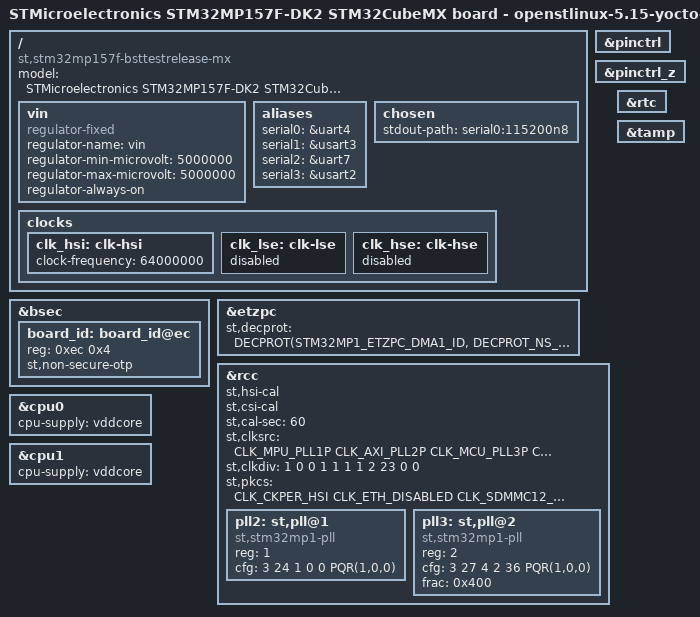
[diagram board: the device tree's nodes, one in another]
/* SPDX-License-Identifier: (GPL-2.0+ OR BSD-3-Clause) */
/*
 * Copyright (C) STMicroelectronics 2024 - All Rights Reserved
 * Author: STM32CubeMX code generation for STMicroelectronics.
 */

/* For more information on Device Tree configuration, please refer to
 * https://wiki.st.com/stm32mpu/wiki/Category:Device_tree_configuration
 */

/dts-v1/;
#include <dt-bindings/pinctrl/stm32-pinfunc.h>
#include <dt-bindings/clock/stm32mp1-clksrc.h>
#include <dt-bindings/soc/st,stm32-etzpc.h>

#include "stm32mp157.dtsi"
#include "stm32mp15xf.dtsi"
#include "stm32mp15xxac-pinctrl.dtsi"
/* !!! log : Warning - DDR not configured: unknown DDR dtsi  !!! */
/*#include "???-ddr.dtsi"*/

/* USER CODE BEGIN includes */
#include <dt-bindings/power/stm32mp1-power.h>
/* USER CODE END includes */

/ {
	model = "STMicroelectronics STM32MP157F-DK2 STM32CubeMX board - openstlinux-5.15-yocto-kirkstone-mp1-v22.11.23";
	compatible = "st,stm32mp157f-bsttestrelease-mx", "st,stm32mp157";

	/* !!! log : Warning - no DDR config found: 'memory' node not generated  !!! */

	/*
	memory@??? {
		reg = < ??? >;
	};
	*/

	/* USER CODE BEGIN root */

	vin:vin{
		compatible = "regulator-fixed";
		regulator-name = "vin";
		regulator-min-microvolt = <5000000>;
		regulator-max-microvolt = <5000000>;
		regulator-always-on;
	};

	aliases{
		serial0 = &uart4;
		serial1 = &usart3;
		serial2 = &uart7;
		serial3 = &usart2;
	};

	chosen{
		stdout-path = "serial0:115200n8";
	};
	/* USER CODE END root */

	clocks {
		/* USER CODE BEGIN clocks */
		/* USER CODE END clocks */

		clk_hsi: clk-hsi {
			clock-frequency = <64000000>;

			/* USER CODE BEGIN clk_hsi */
			/* USER CODE END clk_hsi */
		};
		clk_lse: clk-lse {
			status = "disabled";

			/* USER CODE BEGIN clk_lse */
			/* USER CODE END clk_lse */
		};
		clk_hse: clk-hse {
			status = "disabled";

			/* USER CODE BEGIN clk_hse */
			/* USER CODE END clk_hse */
		};
	};

}; /*root*/

&pinctrl {
	/* USER CODE BEGIN pinctrl */
	/* USER CODE END pinctrl */
};

&pinctrl_z {
	/* USER CODE BEGIN pinctrl_z */
	/* USER CODE END pinctrl_z */
};

&bsec{
	status = "okay";

	/* USER CODE BEGIN bsec */

	board_id:board_id@ec{
		reg = <0xec 0x4>;
		st,non-secure-otp;
	};
	/* USER CODE END bsec */
};

&etzpc{
	status = "okay";
	st,decprot = <
	/*"Non Secured" peripherals*/
	DECPROT(STM32MP1_ETZPC_DMA1_ID, DECPROT_NS_RW, DECPROT_UNLOCK)
	DECPROT(STM32MP1_ETZPC_DMAMUX_ID, DECPROT_NS_RW, DECPROT_UNLOCK)
	/*"Secured" peripherals*/
	DECPROT(STM32MP1_ETZPC_STGENC_ID, DECPROT_S_RW, DECPROT_UNLOCK)
	/*"Mcu Isolation" peripherals*/
	DECPROT(STM32MP1_ETZPC_ADC_ID, DECPROT_MCU_ISOLATION, DECPROT_UNLOCK)
	DECPROT(STM32MP1_ETZPC_DMA2_ID, DECPROT_MCU_ISOLATION, DECPROT_UNLOCK)
	DECPROT(STM32MP1_ETZPC_TIM3_ID, DECPROT_MCU_ISOLATION, DECPROT_UNLOCK)
	DECPROT(STM32MP1_ETZPC_TIM5_ID, DECPROT_MCU_ISOLATION, DECPROT_UNLOCK)

	/*Restriction: following IDs are not managed  - please to use User-Section if needed:
		  STM32MP1_ETZPC_SRAMx_ID  STM32MP1_ETZPC_RETRAM_ID  STM32MP1_ETZPC_BKPSRAM_ID*/

	/* USER CODE BEGIN etzpc_decprot */
		/*STM32CubeMX generates a basic and standard configuration for ETZPC.
		Additional device configurations can be added here if needed.
		"etzpc" node could be also overloaded in "addons" User-Section.*/
	/* USER CODE END etzpc_decprot */
	>;

	/* USER CODE BEGIN etzpc */
	/* USER CODE END etzpc */
};

&rcc{
	status = "okay";

	/* USER CODE BEGIN rcc */
	st,hsi-cal;
	st,csi-cal;
	st,cal-sec = <60>;
	/* USER CODE END rcc */

	st,clksrc = <
		CLK_MPU_PLL1P
		CLK_AXI_PLL2P
		CLK_MCU_PLL3P
		CLK_PLL12_HSI
		CLK_PLL3_HSI
		CLK_PLL4_HSI
		CLK_RTC_LSI
		CLK_MCO1_DISABLED
		CLK_MCO2_DISABLED
	>;
	st,clkdiv = <
		1 		/*MPU*/
		0 		/*AXI*/
		0 		/*MCU*/
		1 		/*APB1*/
		1 		/*APB2*/
		1 		/*APB3*/
		1 		/*APB4*/
		2 		/*APB5*/
		23 		/*RTC*/
		0 		/*MCO1*/
		0 		/*MCO2*/
	>;
	st,pkcs = <
		CLK_CKPER_HSI
		CLK_ETH_DISABLED
		CLK_SDMMC12_DISABLED
		CLK_STGEN_HSI
		CLK_USBPHY_DISABLED
		CLK_SPI2S1_DISABLED
		CLK_SPI2S23_DISABLED
		CLK_SPI45_DISABLED
		CLK_SPI6_DISABLED
		CLK_I2C46_DISABLED
		CLK_SDMMC3_DISABLED
		CLK_ADC_CKPER
		CLK_CEC_DISABLED
		CLK_I2C12_DISABLED
		CLK_I2C35_DISABLED
		CLK_UART1_DISABLED
		CLK_UART24_DISABLED
		CLK_UART35_DISABLED
		CLK_UART6_DISABLED
		CLK_UART78_DISABLED
		CLK_SPDIF_DISABLED
		CLK_SAI1_DISABLED
		CLK_SAI2_DISABLED
		CLK_SAI3_DISABLED
		CLK_SAI4_DISABLED
		CLK_LPTIM1_DISABLED
		CLK_LPTIM23_DISABLED
		CLK_LPTIM45_DISABLED
	>;
	pll2:st,pll@1 {
		compatible = "st,stm32mp1-pll";
		reg = <1>;
		cfg = < 3 24 1 0 0 PQR(1,0,0) >;
	};
	pll3:st,pll@2 {
		compatible = "st,stm32mp1-pll";
		reg = <2>;
		cfg = < 3 27 4 2 36 PQR(1,0,0) >;
		frac = < 0x400 >;
	};
};

&rtc{
	status = "okay";

	/* USER CODE BEGIN rtc */
	/* USER CODE END rtc */
};

&tamp{
	status = "okay";

	/* USER CODE BEGIN tamp */
	/* USER CODE END tamp */
};

/* USER CODE BEGIN addons */

&cpu0{
	cpu-supply = <&vddcore>;
};

&cpu1{
	cpu-supply = <&vddcore>;
};
/* USER CODE END addons */

